# STM32U5F9xx register map
File version: 1.0
Registers are 32-bit, read-write, reset 0x0 unless marked. A register's access mark holds for its fields unless they carry their own. Offsets are from the block's base; [hi:lo] are bit positions; {n}, {i} and the like mark numbered series.

## MDF1 — MDF/ADF
Base 0x40025000
Same registers: MDF1_S 0x50025000
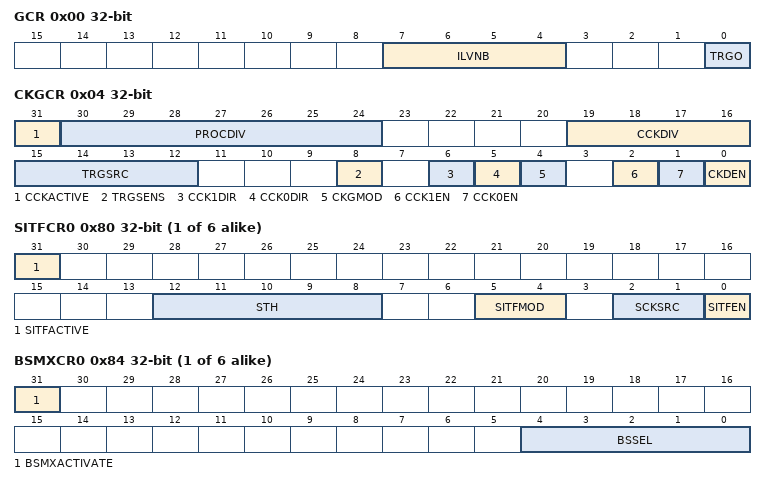
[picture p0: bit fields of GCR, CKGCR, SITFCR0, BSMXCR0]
0x00 GCR — MDF Global Control register
  [7:4] ILVNB — Interleaved Number
  [0] TRGO — Trigger output control
0x04 CKGCR — MDF Clock Generator Control Register
  [31] CCKACTIVE — Clock generator active flag
  [30:24] PROCDIV — Divider to control the serial interface clock
  [19:16] CCKDIV — Divider to control the MDF_CCK clock
  [15:12] TRGSRC — Digital Filter trigger signal selection
  [8] TRGSENS — CKGEN trigger sensitivity selection
  [6] CCK1DIR — CCK1 clock direction
  [5] CCK0DIR — CCK0 clock direction
  [4] CKGMOD — Clock genartor mode
  [2] CCK1EN — CCK1 clock enable
  [1] CCK0EN — CCK0 clock enable
  [0] CKDEN — CKGEN diveders enable
0x20 OR — MDF Option Register
  [31:0] OPTION — Option Control Bits
{0x80+0x80*i} SITFCR{i} (i=0..5) — MDF Serial Interface Control Register
  [31] SITFACTIVE — Serial interface active flag
  [12:8] STH — Manchester Symbol threshold / SPI threshold
  [5:4] SITFMOD — Serial interface type
  [2:1] SCKSRC — Serial clock source
  [0] SITFEN — Serial interface enable
{0x84+0x80*i} BSMXCR{i} (i=0..5) — MDF Bitstream Matrix Control Register
  [31] BSMXACTIVATE — Bit Streal activation flag
  [4:0] BSSEL — Bit Streal selection
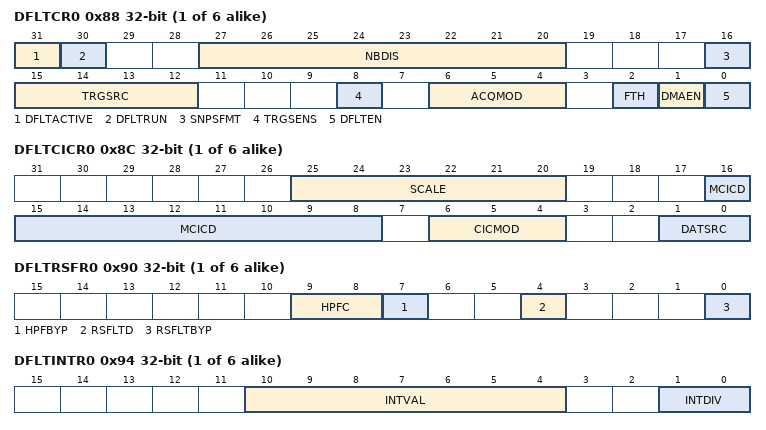
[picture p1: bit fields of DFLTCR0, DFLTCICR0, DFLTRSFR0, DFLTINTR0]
{0x88+0x80*i} DFLTCR{i} (i=0..5) — MDF Digital Filter Control Register
  [31] DFLTACTIVE — Digital filter active flag
  [30] DFLTRUN — Digital filter run status flag
  [27:20] NBDIS — Number of samples to be discard
  [16] SNPSFMT — SnapShot Data format
  [15:12] TRGSRC — Digital filter trigger signal selection
  [8] TRGSENS — Digital filter trigger sensitivity selection
  [6:4] ACQMOD — Digital filter trigger mode
  [2] FTH — RXFIFO Threshold selection
  [1] DMAEN — DMA request enable
  [0] DFLTEN — Digital filter enable
{0x8C+0x80*i} DFLTCICR{i} (i=0..5) — MDF MCIC Configuration Register
  [25:20] SCALE — Scaling factor selection
  [16:8] MCICD — CIC decimation ratio selection
  [6:4] CICMOD — Select the CIC Mode
  [1:0] DATSRC — Source Data for the digital filter
{0x90+0x80*i} DFLTRSFR{i} (i=0..5) — MDF Reshape Filter Configuration Register
  [9:8] HPFC — High-pass filter cut-off frequency
  [7] HPFBYP — High-pass filter bypass
  [4] RSFLTD — Reshape filter decimation ratio
  [0] RSFLTBYP — Reshape filter bypass
{0x94+0x80*i} DFLTINTR{i} (i=0..5) — MDF Integrator Configuration Register
  [10:4] INTVAL — Integrator value selection
  [1:0] INTDIV — Integrator output dividion
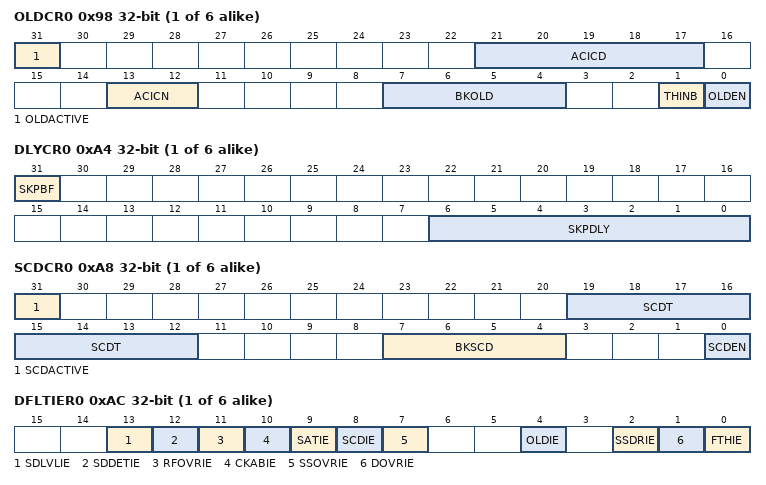
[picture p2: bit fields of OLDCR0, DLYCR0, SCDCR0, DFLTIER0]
{0x98+0x80*i} OLDCR{i} (i=0..5) — MDF Out-Of Limit Detector Control Register
  [31] OLDACTIVE — OLD active flag
  [21:17] ACICD — OLD CIC decimation ratio selection
  [13:12] ACICN — OLD CIC order selection
  [7:4] BKOLD — Bteak signal assignment for OLD
  [1] THINB — OLD threshold in band
  [0] OLDEN — OLD enable
{0x9C+0x80*i} OLDTHLR{i} (i=0..5) — MDF OLD Threshold Low Register
  [25:0] OLDTHL — OLD Low threshold value
{0xA0+0x80*i} OLDTHHR{i} (i=0..5) — MDF OLD Threshold High Register
  [25:0] OLDTHH — OLD High threshold value
{0xA4+0x80*i} DLYCR{i} (i=0..5) — MDF Delay control Register
  [31] SKPBF — DSkip Busy Flag
  [6:0] SKPDLY — Delay to apply to a bitstream
{0xA8+0x80*i} SCDCR{i} (i=0..5) — MDF short circuit detector control Register
  [31] SCDACTIVE — Short circuit detector active flag
  [19:12] SCDT — Short circuit detector threshold
  [7:4] BKSCD — Break signal assignment to short circuit detector
  [0] SCDEN — Short circuit detector enable
{0xAC+0x80*i} DFLTIER{i} (i=0..5) — MDF DFLT Interrupt enable Register
  [13] SDLVLIE — Sound level value ready interrupt enable
  [12] SDDETIE — SAD interrupt enable
  [11] RFOVRIE — reshape filter overrun interrupt enable
  [10] CKABIE — Clock absence detection interrupt enable
  [9] SATIE — Saturation detection interrupt enable
  [8] SCDIE — Short circuit dtector interrupt enable
  [7] SSOVRIE — Snapshot overrun interrupt enable
  [4] OLDIE — OLD interrupt enable
  [2] SSDRIE — Snapshot data ready interrupt enable
  [1] DOVRIE — Data overflow interrupt enable
  [0] FTHIE — RXFIFO threshold interrupt enable
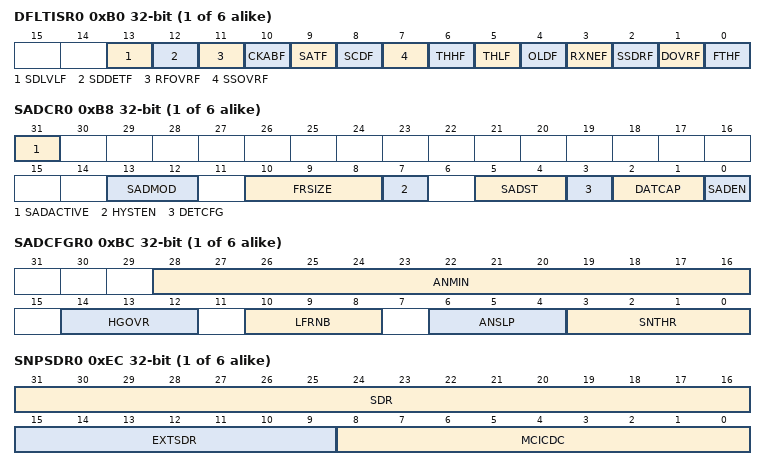
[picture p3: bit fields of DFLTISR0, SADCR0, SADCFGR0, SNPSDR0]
{0xB0+0x80*i} DFLTISR{i} (i=0..5) — MDF DFLT Interrupt status Register
  [13] SDLVLF — Sound level value ready interrupt flag
  [12] SDDETF — SAD interrupt flag
  [11] RFOVRF — reshape filter overrun interrupt flag
  [10] CKABF — Clock absence detection interrupt flag
  [9] SATF — Saturation detection interrupt flag
  [8] SCDF — Short circuit dtector interrupt flag
  [7] SSOVRF — Snapshot overrun interrupt flag
  [6] THHF — OLD interrupt flag
  [5] THLF — OLD interrupt flag
  [4] OLDF — OLD interrupt flag
  [3] RXNEF — Snapshot data ready interrupt flag
  [2] SSDRF — Snapshot data ready interrupt flag
  [1] DOVRF — Data overflow interrupt flag
  [0] FTHF — RXFIFO threshold interrupt flag
{0xB4+0x80*i} OECCR{i} (i=0..5) — MDF
  [25:0] OFFSET — Short circuit detector enable
{0xB8+0x80*i} SADCR{i} (i=0..5) — MDF SAD Control Register
  [31] SADACTIVE — SAD active flag
  [13:12] SADMOD — SAD working mode
  [10:8] FRSIZE — Frame size
  [7] HYSTEN — Hysteresis enable
  [5:4] SADST — SAD state
  [3] DETCFG — SAD trigger event configuration
  [2:1] DATCAP — SAD data capture mode
  [0] SADEN — SAD enable
{0xBC+0x80*i} SADCFGR{i} (i=0..5) — MDF SAD configuration register
  [28:16] ANMIN — Hangover time window
  [14:12] HGOVR — Hangover time window
  [10:8] LFRNB — Number of learning frames
  [6:4] ANSLP — Ambiant noise slope control
  [3:0] SNTHR — Signal to noise threshold
{0xC0+0x80*i} SADSDLVR{i} (i=0..5) — MDF SAD Sound level Register
  [14:0] SDLVL — Short term sound level
{0xC4+0x80*i} SADANLVR{i} (i=0..5) — MDF SAD Ambient Noise level Register
  [14:0] ANLVL — Ambiant noise level estimation
{0xEC+0x80*i} SNPSDR{i} (i=0..5) — MDF Snapshot Data Register
  [31:16] SDR — Extended data size
  [15:9] EXTSDR — Extended data size
  [8:0] MCICDC — MCIC decimation counter
{0xF0+0x80*i} DFLTDR{i} (i=0..5) — MDF Digital Filter Data Register
  [31:8] DR — MCIC decimation counter

## ADF1 — MDF/ADF
Base 0x46024000
Same registers: ADF1_S 0x56024000
Registers as MDF1, without SITFCR{n} (n=1..5), BSMXCR{n} (n=1..5), DFLTCR{n} (n=1..5), DFLTCICR{n} (n=1..5), DFLTRSFR{n} (n=1..5), DFLTINTR{n} (n=1..5), OLDCR{n} (n=1..5), OLDTHLR{n} (n=1..5), OLDTHHR{n} (n=1..5), DLYCR{n} (n=1..5), SCDCR{n} (n=1..5), DFLTIER{n} (n=1..5), DFLTISR{n} (n=1..5), OECCR{n} (n=1..5), SADCR{n} (n=1..5), SADCFGR{n} (n=1..5), SADSDLVR{n} (n=1..5), SADANLVR{n} (n=1..5), SNPSDR{n} (n=1..5), DFLTDR{n} (n=1..5).
